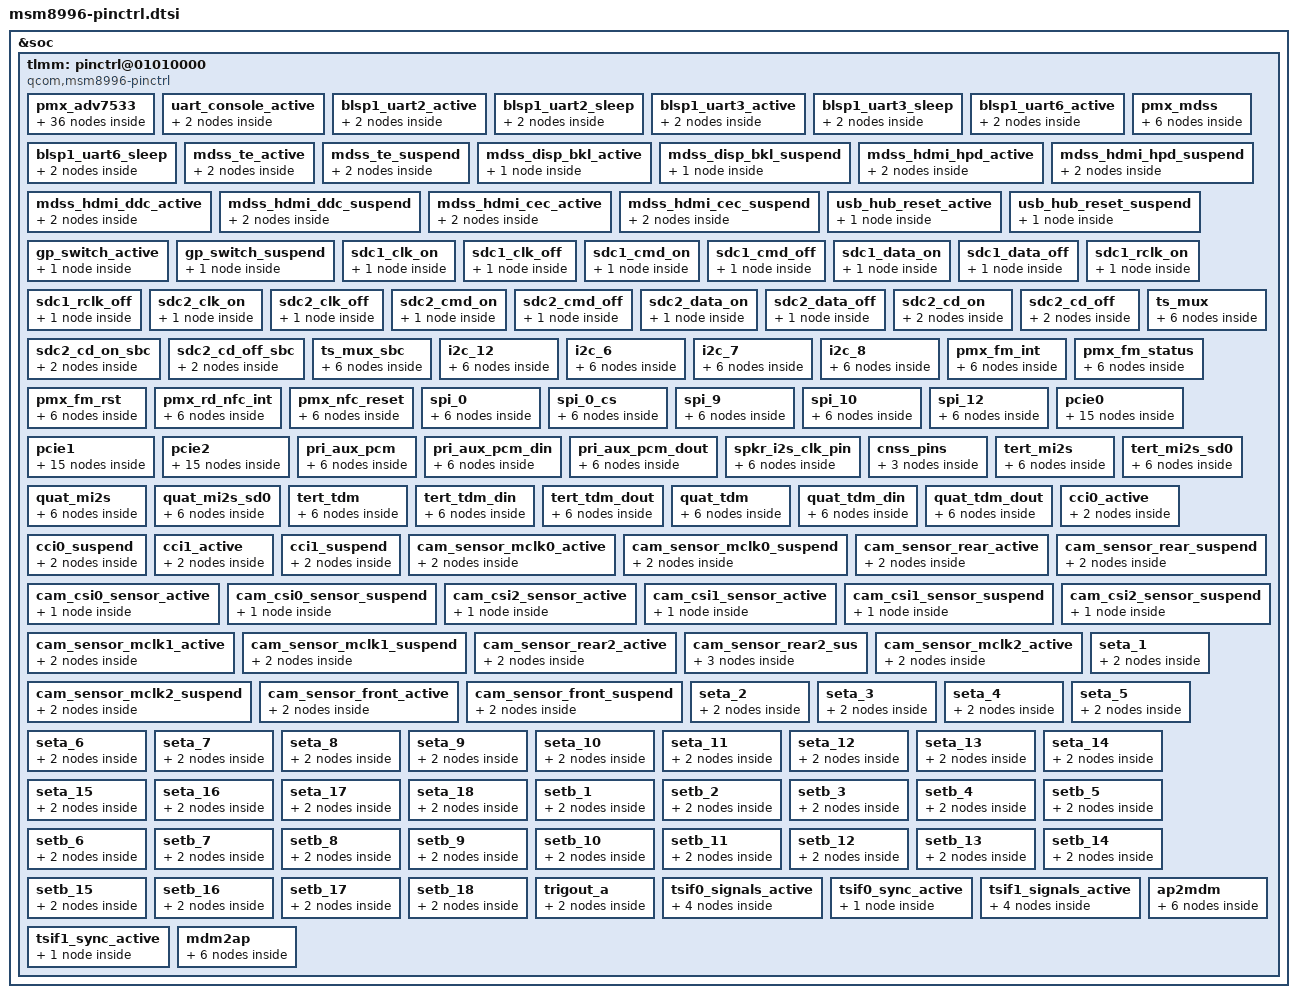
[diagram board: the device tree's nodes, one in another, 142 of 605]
/* Copyright (c) 2014-2015, The Linux Foundation. All rights reserved.
 *
 * This program is free software; you can redistribute it and/or modify
 * it under the terms of the GNU General Public License version 2 and
 * only version 2 as published by the Free Software Foundation.
 *
 * This program is distributed in the hope that it will be useful,
 * but WITHOUT ANY WARRANTY; without even the implied warranty of
 * MERCHANTABILITY or FITNESS FOR A PARTICULAR PURPOSE.  See the
 * GNU General Public License for more details.
 */

&soc {
	tlmm: pinctrl@01010000 {
		compatible = "qcom,msm8996-pinctrl";
		reg = <0x01010000 0x300000>;
		interrupts = <0 208 0>;
		gpio-controller;
		#gpio-cells = <2>;
		interrupt-controller;
		#interrupt-cells = <2>;

		/* add pingrp for adv7533 */
		pmx_adv7533: pmx_adv7533 {
			adv7533_0_int_active: adv7533_0_int_active {
				mux {
					pins = "gpio106";
					function = "gpio";
				};

				config {
					pins = "gpio106";
					drive-strength = <16>; /* 16 mA */
					bias-pull-down; /* pull down */
				};
			};

			adv7533_0_int_suspend: adv7533_0_int_suspend {
				mux {
					pins = "gpio106";
					function = "gpio";
				};

				config {
					pins = "gpio106";
					drive-strength = <16>; /* 16 mA */
					bias-pull-down; /* pull down */
				};
			};

			adv7533_0_hpd_int_active: adv7533_0_hpd_int_active {
				mux {
					pins = "gpio104";
					function = "gpio";
				};

				config {
					pins = "gpio104";
					drive-strength = <16>; /* 16 mA */
					bias-pull-down; /* pull down */
				};
			};

			adv7533_0_hpd_int_suspend: adv7533_0_hpd_int_suspend {
				mux {
					pins = "gpio104";
					function = "gpio";
				};

				config {
					pins = "gpio104";
					drive-strength = <16>; /* 16 mA */
					bias-pull-down; /* pull down */
				};
			};

			adv7533_0_switch_active: adv7533_0_switch_active {
				mux {
					pins = "gpio105";
					function = "gpio";
					bias-pull-down; /* pull down */
				};

				config {
					pins = "gpio105";
					drive-strength = <16>; /* 16 mA */
					bias-pull-down; /* pull down */
				};
			};

			adv7533_0_switch_suspend: adv7533_0_switch_suspend {
				mux {
					pins = "gpio105";
					function = "gpio";
				};

				config {
					pins = "gpio105";
					drive-strength = <16>; /* 16 mA */
				};
			};
			adv7533_1_int_active: adv7533_1_int_active {
				mux {
					pins = "gpio108";
					function = "gpio";
				};

				config {
					pins = "gpio108";
					drive-strength = <16>; /* 16 mA */
					bias-pull-down; /* pull down */
				};
			};

			adv7533_1_int_suspend: adv7533_1_int_suspend {
				mux {
					pins = "gpio108";
					function = "gpio";
				};

				config {
					pins = "gpio108";
					drive-strength = <16>; /* 16 mA */
					bias-pull-down; /* pull down */
				};
			};

			adv7533_1_hpd_int_active: adv7533_1_hpd_int_active {
				mux {
					pins = "gpio103";
					function = "gpio";
				};

				config {
					pins = "gpio103";
					drive-strength = <16>; /* 16 mA */
					bias-pull-down; /* pull down */
				};
			};

			adv7533_1_hpd_int_suspend: adv7533_1_hpd_int_suspend {
				mux {
					pins = "gpio103";
					function = "gpio";
				};

				config {
					pins = "gpio103";
					drive-strength = <16>; /* 16 mA */
					bias-pull-down; /* pull down */
				};
			};

			adv7533_1_switch_active: adv7533_1_switch_active {
				mux {
					pins = "gpio107";
					function = "gpio";
					bias-pull-down; /* pull down */
				};

				config {
					pins = "gpio107";
					drive-strength = <16>; /* 16 mA */
					bias-pull-down; /* pull down */
				};
			};

			adv7533_1_switch_suspend: adv7533_1_switch_suspend {
				mux {
					pins = "gpio107";
					function = "gpio";
				};

				config {
					pins = "gpio107";
					drive-strength = <16>; /* 16 mA */
				};
			};
		};

		uart_console_active: uart_console_active {
			mux {
				pins = "gpio4", "gpio5";
				function = "blsp_uart8";
			};

			config {
				pins = "gpio4", "gpio5";
				drive-strength = <2>;
				bias-disable;
			};
		};

		blsp1_uart2_active: blsp1_uart2_active {
			mux {
				pins = "gpio41", "gpio42", "gpio43", "gpio44";
				function = "blsp_uart2";
			};

			config {
				pins = "gpio41", "gpio42", "gpio43", "gpio44";
				drive-strength = <2>;
				bias-disable;
			};
		};

		blsp1_uart2_sleep: blsp1_uart2_sleep {
			mux {
				pins = "gpio41", "gpio42", "gpio43", "gpio44";
				function = "gpio";
			};

			config {
				pins = "gpio41", "gpio42", "gpio43", "gpio44";
				drive-strength = <2>;
				bias-disable;
			};
		};


		blsp1_uart3_active: blsp1_uart3_active {
			mux {
				pins = "gpio45", "gpio46", "gpio47", "gpio48";
				function = "blsp_uart3";
			};

			config {
				pins = "gpio45", "gpio46", "gpio47", "gpio48";
				drive-strength = <2>;
				bias-disable;
			};
		};

		blsp1_uart3_sleep: blsp1_uart3_sleep {
			mux {
				pins = "gpio45", "gpio46", "gpio47", "gpio48";
				function = "gpio";
			};

			config {
				pins = "gpio45", "gpio46", "gpio47", "gpio48";
				drive-strength = <2>;
				bias-disable;
			};
		};


		blsp1_uart6_active: blsp1_uart6_active {
			mux {
				pins = "gpio25", "gpio26", "gpio27", "gpio28";
				function = "blsp_uart6";
			};

			config {
				pins = "gpio25", "gpio26", "gpio27", "gpio28";
				drive-strength = <2>;
				bias-disable;
			};
		};

		blsp1_uart6_sleep: blsp1_uart6_sleep {
			mux {
				pins = "gpio25", "gpio26", "gpio27", "gpio28";
				function = "gpio";
			};

			config {
				pins = "gpio25", "gpio26", "gpio27", "gpio28";
				drive-strength = <2>;
				bias-disable;
			};
		};


		pmx_mdss: pmx_mdss {
			mdss_dsi_active: mdss_dsi_active {
				mux {
					pins = "gpio8";
					function = "gpio";
				};

				pmx_mdss {
					pins = "gpio8";
					drive-strength = <8>; /* 8 mA */
					bias-disable = <0>; /* no pull */
					output-high;
				};
			};
			mdss_dsi_suspend: mdss_dsi_suspend {
				mux {
					pins = "gpio8";
					function = "gpio";
				};

				config {
					pins = "gpio8";
					drive-strength = <2>; /* 2 mA */
					bias-pull-down; /* pull down */
				};
			};
		};

		mdss_te_active: mdss_te_active {
			mux {
				pins = "gpio10";
				function = "mdp_vsync";
			};
			config {
				pins = "gpio10";
				drive-strength = <2>; /* 8 mA */
				bias-pull-down; /* pull down*/
			};
		};


		mdss_te_suspend: mdss_te_suspend {
			mux {
				pins = "gpio10";
				function = "mdp_vsync";
			};
			config {
				pins = "gpio10";
				drive-strength = <2>; /* 2 mA */
				bias-pull-down; /* pull down */
			};
		};

		mdss_disp_bkl_active: mdss_disp_bkl_active {
			config {
				pins = "gpio135";
				drive-strength = <8>; /* 8 mA */
				bias-disable; /* no pull */
				output-high;
			};
		};

		mdss_disp_bkl_suspend: mdss_disp_bkl_suspend {
			config {
				pins = "gpio135";
				drive-strength = <2>; /* 2 mA */
				bias-pull-down; /* pull down */
			};
		};

		mdss_hdmi_hpd_active: mdss_hdmi_hpd_active {
			mux {
				pins = "gpio34";
				function = "hdmi_hot";
			};

			config {
				pins = "gpio34";
				bias-pull-down;
				drive-strength = <16>;
			};
		};

		mdss_hdmi_hpd_suspend: mdss_hdmi_hpd_suspend {
			mux {
				pins = "gpio34";
				function = "hdmi_hot";
			};

			config {
				pins = "gpio34";
				bias-pull-down;
				drive-strength = <2>;
			};
		};

		mdss_hdmi_ddc_active: mdss_hdmi_ddc_active {
			mux {
				pins = "gpio32", "gpio33";
				function = "hdmi_ddc";
			};

			config {
				pins = "gpio32", "gpio33";
				drive-strength = <2>;
				bias-pull-up;
			};
		};

		mdss_hdmi_ddc_suspend: mdss_hdmi_ddc_suspend {
			mux {
				pins = "gpio32", "gpio33";
				function = "hdmi_ddc";
			};

			config {
				pins = "gpio32", "gpio33";
				drive-strength = <2>;
				bias-pull-down;
			};
		};

		mdss_hdmi_cec_active: mdss_hdmi_cec_active {
			mux {
				pins = "gpio31";
				function = "hdmi_cec";
			};

			config {
				pins = "gpio31";
				drive-strength = <2>;
				bias-pull-up;
			};
		};

		mdss_hdmi_cec_suspend: mdss_hdmi_cec_suspend {
			mux {
				pins = "gpio31";
				function = "hdmi_cec";
			};

			config {
				pins = "gpio31";
				drive-strength = <2>;
				bias-pull-down;
			};
		};

		usb_hub_reset_active: usb_hub_reset_active {
			usb_hub_reset_active {
				pins = "gpio103";
				drive-strength = <8>; /* 8 mA */
				bias-pull-up;  /* pull up */
				output-high;
			};
		};

		usb_hub_reset_suspend: usb_hub_reset_suspend {
			usb_hub_reset_suspend {
				pins = "gpio103";
				drive-strength = <2>; /* 2 mA */
				bias-disable= <0>; /* no pull */
			};
		};


		gp_switch_active: gp_switch_active {
			gp_switch_active {
				pins = "gpio127";
				drive-strength = <8>; /* 8 mA */
				bias-pull-up;  /* pull up */
				output-low;
			};
		};

		gp_switch_suspend: gp_switch_suspend {
			gp_switch_suspend {
				pins = "gpio127";
				drive-strength = <2>; /* 2 mA */
				bias-disable= <0>; /* no pull */
			};
		};


		sdc1_clk_on: sdc1_clk_on {
			config {
				pins = "sdc1_clk";
				bias-disable;		/* NO pull */
				drive-strength = <16>;	/* 16 MA */
			};
		};

		sdc1_clk_off: sdc1_clk_off {
			config {
				pins = "sdc1_clk";
				bias-disable;		/* NO pull */
				drive-strength = <2>;	/* 2 MA */
			};
		};

		sdc1_cmd_on: sdc1_cmd_on {
			config {
				pins = "sdc1_cmd";
				bias-pull-up;		/* pull up */
				drive-strength = <10>;	/* 10 MA */
			};
		};

		sdc1_cmd_off: sdc1_cmd_off {
			config {
				pins = "sdc1_cmd";
				num-grp-pins = <1>;
				bias-pull-up;		/* pull up */
				drive-strength = <2>;	/* 2 MA */
			};
		};

		sdc1_data_on: sdc1_data_on {
			config {
				pins = "sdc1_data";
				bias-pull-up;		/* pull up */
				drive-strength = <10>;	/* 10 MA */
			};
		};

		sdc1_data_off: sdc1_data_off {
			config {
				pins = "sdc1_data";
				bias-pull-up;		/* pull up */
				drive-strength = <2>;	/* 2 MA */
			};
		};

		sdc1_rclk_on: sdc1_rclk_on {
			config {
				pins = "sdc1_rclk";
				bias-pull-down;		/* pull down */
			};
		};

		sdc1_rclk_off: sdc1_rclk_off {
			config {
				pins = "sdc1_rclk";
				bias-pull-down;		/* pull down */
			};
		};

		sdc2_clk_on: sdc2_clk_on {
			config {
				pins = "sdc2_clk";
				bias-disable;		/* NO pull */
				drive-strength = <16>;	/* 16 MA */
			};
		};

		sdc2_clk_off: sdc2_clk_off {
			config {
				pins = "sdc2_clk";
				bias-disable;		/* NO pull */
				drive-strength = <2>;	/* 2 MA */
			};
		};

		sdc2_cmd_on: sdc2_cmd_on {
			config {
				pins = "sdc2_cmd";
				bias-pull-up;		/* pull up */
				drive-strength = <10>;	/* 10 MA */
			};
		};

		sdc2_cmd_off: sdc2_cmd_off {
			config {
				pins = "sdc2_cmd";
				bias-pull-up;		/* pull up */
				drive-strength = <2>;	/* 2 MA */
			};
		};

		sdc2_data_on: sdc2_data_on {
			config {
				pins = "sdc2_data";
				bias-pull-up;		/* pull up */
				drive-strength = <10>;	/* 10 MA */
			};
		};

		sdc2_data_off: sdc2_data_off {
			config {
				pins = "sdc2_data";
				bias-pull-up;		/* pull up */
				drive-strength = <2>;	/* 2 MA */
			};
		};

		sdc2_cd_on: sdc2_cd_on {
			mux {
				pins = "gpio95";
				function = "gpio";
			};

			config {
				pins = "gpio95";
				bias-pull-up;		/* pull up */
				drive-strength = <16>;	/* 16 MA */
			};
		};

		sdc2_cd_off: sdc2_cd_off {
			mux {
				pins = "gpio95";
				function = "gpio";
			};

			config {
				pins = "gpio95";
				bias-pull-up;		/* pull up */
				drive-strength = <2>;	/* 2 MA */
			};
		};

		sdc2_cd_on_sbc: sdc2_cd_on_sbc {
			mux {
				pins = "gpio38";
				function = "gpio";
			};

			config {
				pins = "gpio38";
				bias-pull-up;		/* pull up */
				drive-strength = <16>;	/* 16 MA */
			};
		};

		sdc2_cd_off_sbc: sdc2_cd_off_sbc {
			mux {
				pins = "gpio38";
				function = "gpio";
			};

			config {
				pins = "gpio38";
				bias-pull-up;		/* pull up */
				drive-strength = <2>;	/* 2 MA */
			};
		};

		ts_mux {
			ts_active: ts_active {
				mux {
					pins = "gpio89", "gpio125";
					function = "gpio";
				};

				config {
					pins = "gpio89", "gpio125";
					drive-strength = <16>;
					bias-pull-up;
				};
			};

			ts_suspend: ts_suspend {
				mux {
					pins = "gpio89", "gpio125";
					function = "gpio";
				};

				config {
					pins = "gpio89", "gpio125";
					drive-strength = <2>;
					bias-disable;
				};
			};
		};

		ts_mux_sbc {
			ts_active_sbc: ts_active_sbc {
				mux {
					pins = "gpio29", "gpio125";
					function = "gpio";
				};

				config_sbc {
					pins = "gpio29", "gpio125";
					drive-strength = <16>;
					bias-pull-up;
				};
		};

			ts_suspend_sbc: ts_suspend_sbc {
				mux {
					pins = "gpio29", "gpio125";
					function = "gpio";
				};

				config {
					pins = "gpio29", "gpio125";
					drive-strength = <2>;
					bias-disable;
				};
			};
		};
		i2c_12 {
                        i2c_12_active: i2c_12_active {
				mux {
					pins = "gpio87", "gpio88";
					function = "blsp_i2c12";
				};

				config {
					pins = "gpio87", "gpio88";
					drive-strength = <2>;
					bias-disable;
				};
			};

			i2c_12_sleep: i2c_12_sleep {
				mux {
					pins = "gpio87", "gpio88";
					function = "blsp_i2c12";
				};

				config {
					pins = "gpio87", "gpio88";
					drive-strength = <2>;
					bias-pull-up;
				};
			};
		};

		i2c_6 {
			i2c_6_active: i2c_6_active {
				mux {
					pins = "gpio27", "gpio28";
					function = "blsp_i2c6";
				};

				config {
					pins = "gpio27", "gpio28";
					drive-strength = <2>;
					bias-disable;
				};
			};

			i2c_6_sleep: i2c_6_sleep {
				mux {
					pins = "gpio27", "gpio28";
					function = "blsp_i2c6";
				};

				config {
					pins = "gpio27", "gpio28";
					drive-strength = <2>;
					bias-pull-up;
				};
			};
		};

		i2c_7 {
			i2c_7_active: i2c_7_active {
				mux {
					pins = "gpio55", "gpio56";
					function = "blsp_i2c7";
				};

				config {
					pins = "gpio55", "gpio56";
					drive-strength = <2>;
					bias-disable;
				};
			};

			i2c_7_sleep: i2c_7_sleep {
				mux {
					pins = "gpio55", "gpio56";
					function = "blsp_i2c7";
				};

				config {
					pins = "gpio55", "gpio56";
					drive-strength = <2>;
					bias-pull-up;
				};
			};
		};

		i2c_8 {
			i2c_8_active: i2c_8_active {
				mux {
					pins = "gpio6", "gpio7";
					function = "blsp_i2c8";
				};

				config {
					pins = "gpio6", "gpio7";
					drive-strength = <4>;
					bias-disable;
				};
			};

			i2c_8_sleep: i2c_8_sleep {
				mux {
					pins = "gpio6", "gpio7";
					function = "blsp_i2c8";
				};

				config {
					pins = "gpio6", "gpio7";
					drive-strength = <4>;
					bias-pull-up;
				};
			};
		};

		pmx_fm_int {
			fm_int_active: fm_int_active {
				mux {
					pins = "gpio38";
					function = "gpio";
				};

				config {
					pins = "gpio38";
					drive-strength = <16>;
					bias-pull-up;
				};
			};

		fm_int_suspend: fm_int_suspend {
				mux {
					pins = "gpio38";
					function = "gpio";
				};

				config {
					pins = "gpio38";
					drive-strength = <16>;
					bias-pull-up;
				};
			};
		};

		pmx_fm_status {
			fm_status_int_active: fm_status_int_active {
				mux {
					pins = "gpio78";
					function = "gpio";
				};

				config {
					pins = "gpio78";
					drive-strength = <16>;
					bias-pull-up;
				};
			};

			fm_status_int_suspend: fm_status_int_suspend {
				mux {
					pins = "gpio78";
					function = "gpio";
				};

				config {
					pins = "gpio78";
					drive-strength = <16>;
					bias-pull-up;
				};
			};
		};

		pmx_fm_rst {
			fm_rst_active: fm_rst_active {
				mux {
					pins = "gpio39";
					function = "gpio";
				};

				config {
					pins = "gpio39";
					drive-strength = <16>;
					bias-pull-down;
				};
			};

			fm_rst_suspend: fm_rst_suspend {
				mux {
					pins = "gpio39";
					function = "gpio";
				};

				config {
					pins = "gpio39";
					drive-strength = <16>;
					bias-pull-down;
				};
			};
		};

		pmx_rd_nfc_int {
			nfc_int_active: active {
				mux {
					pins = "gpio9";
					function = "gpio";
				};

				config {
					pins = "gpio9";
					drive-strength = <6>;
					bias-pull-up;
				};
			};

			nfc_int_suspend: suspend {
				mux {
					pins = "gpio9";
					function = "gpio";
				};

				config {
					pins = "gpio9";
					drive-strength = <6>;
					bias-pull-up;
				};
			};
		};

		pmx_nfc_reset {
			nfc_disable_active: active {
				mux {
					pins = "gpio12";
					function = "gpio";
				};

				config {
					pins = "gpio12";
					drive-strength = <6>;
					bias-pull-up;
				};
			};

			nfc_disable_suspend: suspend {
				mux {
					pins = "gpio12";
					function = "gpio";
				};

				config {
					pins = "gpio12";
					drive-strength = <6>;
					bias-disable;
				};
			};
		};

		spi_0 {
			spi_0_active: spi_0_active {
				mux {
					pins = "gpio0", "gpio1",
						"gpio2", "gpio3";
					function = "blsp_spi1";
				};

				config {
					pins = "gpio0", "gpio1",
						"gpio2", "gpio3";
					drive-strength = <6>;
					bias-disable;
				};
			};

			spi_0_sleep: spi_0_sleep {
				mux {
					pins = "gpio0", "gpio1",
						"gpio2", "gpio3";
					function = "blsp_spi1";
				};

				config {
					pins = "gpio0", "gpio1",
						"gpio2", "gpio3";
					drive-strength = <6>;
					bias-disable;
				};
			};
		};

		spi_0_cs {
			spi_0_cs_active: spi_0_cs_active {
				mux {
					pins = "gpio24", "gpio90";
					function = "blsp1_spi";
				};

				config {
					pins = "gpio24", "gpio90";
					drive-strength = <6>;
					bias-pull-up;
				};
			};

			spi_0_cs_sleep: spi_0_cs_sleep {
				mux {
					pins = "gpio24", "gpio90";
					function = "blsp1_spi";
				};

				config {
					pins = "gpio24", "gpio90";
					drive-strength = <6>;
					bias-pull-up;
				};
			};
		};

		spi_9 {
			spi_9_active: spi_9_active {
				mux {
					pins = "gpio49", "gpio50", "gpio51",
								"gpio52";
					function = "blsp_spi9";
				};

				config {
					pins = "gpio49", "gpio50", "gpio51",
								"gpio52";
					drive-strength = <6>;
					bias-disable;
				};
			};

			spi_9_sleep: spi_9_sleep {
				mux {
					pins = "gpio49", "gpio50", "gpio51",
								"gpio52";
					function = "blsp_spi9";
				};

				config {
					pins = "gpio49", "gpio50", "gpio51",
								"gpio52";
					drive-strength = <6>;
					bias-disable;
				};
			};
		};

		spi_10 {
			spi_10_active: spi_10_active {
				mux {
					pins = "gpio8", "gpio9", "gpio10",
								"gpio11";
					function = "blsp_spi10";
				};

				config {
					pins = "gpio8", "gpio9", "gpio10",
								"gpio11";
					drive-strength = <6>;
					bias-disable;
				};
			};

			spi_10_sleep: spi_10_sleep {
				mux {
					pins = "gpio8", "gpio9", "gpio10",
								"gpio11";
					function = "blsp_spi10";
				};

				config {
					pins = "gpio8", "gpio9", "gpio10",
								"gpio11";
					drive-strength = <6>;
					bias-disable;
				};
			};
		};

		spi_12 {
			spi_12_active: spi_12_active {
				mux {
					pins = "gpio85", "gpio86", "gpio87",
								"gpio88";
					function = "blsp_spi12";
				};

				config {
					pins = "gpio85", "gpio86", "gpio87",
								"gpio88";
					drive-strength = <6>;
					bias-disable;
				};
			};

			spi_12_sleep: spi_12_sleep {
				mux {
					pins = "gpio85", "gpio86", "gpio87",
								"gpio88";
					function = "blsp_spi12";
				};

				config {
					pins = "gpio85", "gpio86", "gpio87",
								"gpio88";
					drive-strength = <6>;
					bias-disable;
				};
			};
		};

		pcie0 {
			pcie0_clkreq_default: pcie0_clkreq_default {
				mux {
					pins = "gpio36";
					function = "pci_e0";
				};

				config {
					pins = "gpio36";
					drive-strength = <2>;
					bias-pull-up;
				};
			};

			pcie0_perst_default: pcie0_perst_default {
				mux {
					pins = "gpio35";
					function = "gpio";
				};

				config {
					pins = "gpio35";
					drive-strength = <2>;
					bias-pull-down;
				};
			};

			pcie0_wake_default: pcie0_wake_default {
				mux {
					pins = "gpio37";
					function = "gpio";
				};

				config {
					pins = "gpio37";
					drive-strength = <2>;
					bias-pull-up;
				};
			};

			pcie0_clkreq_sleep: pcie0_clkreq_sleep {
				mux {
					pins = "gpio36";
					function = "gpio";
				};

				config {
					pins = "gpio36";
					drive-strength = <2>;
					bias-disable;
				};
			};

			pcie0_wake_sleep: pcie0_wake_sleep {
				mux {
					pins = "gpio37";
					function = "gpio";
				};

				config {
					pins = "gpio37";
					drive-strength = <2>;
					bias-disable;
				};
			};
		};

		pcie1 {
			pcie1_clkreq_default: pcie1_clkreq_default {
				mux {
					pins = "gpio131";
					function = "pci_e1";
				};

				config {
					pins = "gpio131";
					drive-strength = <2>;
					bias-pull-up;
				};
			};

			pcie1_perst_default: pcie1_perst_default {
				mux {
					pins = "gpio130";
					function = "gpio";
				};

				config {
					pins = "gpio130";
					drive-strength = <2>;
					bias-pull-down;
				};
			};

			pcie1_wake_default: pcie1_wake_default {
				mux {
					pins = "gpio132";
					function = "gpio";
				};

				config {
					pins = "gpio132";
					drive-strength = <2>;
					bias-pull-down;
				};
			};

			pcie1_clkreq_sleep: pcie1_clkreq_sleep {
				mux {
					pins = "gpio131";
					function = "gpio";
				};

				config {
					pins = "gpio131";
					drive-strength = <2>;
					bias-disable;
				};
			};

			pcie1_wake_sleep: pcie1_wake_sleep {
				mux {
					pins = "gpio132";
					function = "gpio";
				};

				config {
					pins = "gpio132";
					drive-strength = <2>;
					bias-disable;
				};
			};
		};

		pcie2 {
			pcie2_clkreq_default: pcie2_clkreq_default {
				mux {
					pins = "gpio115";
					function = "pci_e2";
				};

				config {
					pins = "gpio115";
					drive-strength = <2>;
					bias-pull-up;
				};
			};

			pcie2_perst_default: pcie2_perst_default {
				mux {
					pins = "gpio114";
					function = "gpio";
				};

				config {
					pins = "gpio114";
					drive-strength = <2>;
					bias-pull-down;
				};
			};

			pcie2_wake_default: pcie2_wake_default {
				mux {
					pins = "gpio116";
					function = "gpio";
				};

				config {
					pins = "gpio116";
					drive-strength = <2>;
					bias-pull-down;
				};
			};

			pcie2_clkreq_sleep: pcie2_clkreq_sleep {
				mux {
					pins = "gpio115";
					function = "gpio";
				};

				config {
					pins = "gpio115";
					drive-strength = <2>;
					bias-disable;
				};
			};

			pcie2_wake_sleep: pcie2_wake_sleep {
				mux {
					pins = "gpio116";
					function = "gpio";
				};

				config {
					pins = "gpio116";
					drive-strength = <2>;
					bias-disable;
				};
			};
		};

		pri_aux_pcm {
			pri_aux_pcm_sleep: pri_aux_pcm_sleep {
				mux {
					pins = "gpio65", "gpio66";
					function = "pri_mi2s";
				};

				config {
					pins = "gpio65", "gpio66";
					drive-strength = <2>;   /* 2 mA */
					bias-pull-down;         /* PULL DOWN */
				};
			};
			pri_aux_pcm_active: pri_aux_pcm_active {
				mux {
					pins = "gpio65", "gpio66";
					function = "pri_mi2s";
				};

				config {
					pins = "gpio65", "gpio66";
					drive-strength = <8>;   /* 8 mA */
					bias-disable;           /* NO PULL */
					output-high;
				};
			};
		};

		pri_aux_pcm_din {
			pri_aux_pcm_din_sleep: pri_aux_pcm_din_sleep {
				mux {
					pins = "gpio67";
					function = "pri_mi2s";
				};

				config {
					pins = "gpio67";
					drive-strength = <2>;   /* 2 mA */
					bias-pull-down;         /* PULL DOWN */
				};
			};
			pri_aux_pcm_din_active: pri_aux_pcm_din_active {
				mux {
					pins = "gpio67";
					function = "pri_mi2s";
				};

				config {
					pins = "gpio67";
					drive-strength = <8>;   /* 8 mA */
					bias-disable;           /* NO PULL */
				};
			};
		};

		pri_aux_pcm_dout {
			pri_aux_pcm_dout_sleep: pri_aux_pcm_dout_sleep {
				mux {
					pins = "gpio68";
					function = "pri_mi2s";
				};

				config {
					pins = "gpio68";
					drive-strength = <2>;   /* 2 mA */
					bias-pull-down;         /* PULL DOWN */
				};
			};
			pri_aux_pcm_dout_active: pri_aux_pcm_dout_active {
				mux {
					pins = "gpio68";
					function = "pri_mi2s";
				};

				config {
					pins = "gpio68";
					drive-strength = <8>;   /* 8 mA */
					bias-disable;           /* NO PULL */
				};
			};
		};

		spkr_i2s_clk_pin {
			spkr_i2s_clk_sleep: spkr_i2s_clk_sleep {
				mux {
					pins = "gpio69";
					function = "spkr_i2s";
				};

				config {
					pins = "gpio69";
					drive-strength = <2>; /* 2 mA */
					bias-pull-down;       /* PULL DOWN */
				};
			};
			spkr_i2s_clk_active: spkr_i2s_clk_active {
				mux {
					pins = "gpio69";
					function = "spkr_i2s";
				};

				config {
					pins = "gpio69";
					drive-strength = <8>; /* 8 mA */
					bias-disable;         /* NO PULL */
				};
			};
		};

		cnss_pins {
			cnss_default: cnss_default {
				mux {
					pins = "gpio46";
					function = "gpio";
				};

				config {
					pins = "gpio46";
					drive-strength = <16>;
					bias-pull-down;
				};
			};
		};

		tert_mi2s {
			tert_mi2s_sleep: tert_mi2s_sleep {
				mux {
					pins = "gpio75", "gpio76";
					function = "ter_mi2s";
				};

				config {
					pins = "gpio75", "gpio76";
					drive-strength = <2>;   /* 2 mA */
					bias-pull-down;         /* PULL DOWN */
				};
			};
			tert_mi2s_active: tert_mi2s_active {
				mux {
					pins = "gpio75", "gpio76";
					function = "ter_mi2s";
				};

				config {
					pins = "gpio75", "gpio76";
					drive-strength = <8>;   /* 8 mA */
					bias-disable;           /* NO PULL */
					output-high;
				};
			};
		};

		tert_mi2s_sd0 {
			tert_mi2s_sd0_sleep: tert_mi2s_sd0_sleep {
				mux {
					pins = "gpio77";
					function = "ter_mi2s";
				};

				config {
					pins = "gpio77";
					drive-strength = <2>;   /* 2 mA */
					bias-pull-down;         /* PULL DOWN */
				};
			};
			tert_mi2s_sd0_active: tert_mi2s_sd0_active {
				mux {
					pins = "gpio77";
					function = "ter_mi2s";
				};

				config {
					pins = "gpio77";
					drive-strength = <8>;   /* 8 mA */
					bias-disable;           /* NO PULL */
				};
			};
		};

		quat_mi2s {
			quat_mi2s_sleep: quat_mi2s_sleep {
				mux {
					pins = "gpio58", "gpio59";
					function = "qua_mi2s";
				};

				config {
					pins = "gpio58", "gpio59";
					drive-strength = <2>;   /* 2 mA */
					bias-pull-down;         /* PULL DOWN */
				};
			};
			quat_mi2s_active: quat_mi2s_active {
				mux {
					pins = "gpio58", "gpio59";
					function = "qua_mi2s";
				};

				config {
					pins = "gpio58", "gpio59";
					drive-strength = <8>;   /* 8 mA */
					bias-disable;           /* NO PULL */
					output-high;
				};
			};
		};

		quat_mi2s_sd0 {
			quat_mi2s_sd0_sleep: quat_mi2s_sd0_sleep {
				mux {
					pins = "gpio60";
					function = "qua_mi2s";
				};

				config {
					pins = "gpio60";
					drive-strength = <2>;   /* 2 mA */
					bias-pull-down;         /* PULL DOWN */
				};
			};
			quat_mi2s_sd0_active: quat_mi2s_sd0_active {
				mux {
					pins = "gpio60";
					function = "qua_mi2s";
				};

				config {
					pins = "gpio60";
					drive-strength = <8>;   /* 8 mA */
					bias-disable;           /* NO PULL */
				};
			};
		};

		tert_tdm {
			tert_tdm_sleep: tert_tdm_sleep {
				mux {
					pins = "gpio75", "gpio76";
					function = "ter_mi2s";
				};

				config {
					pins = "gpio75", "gpio76";
					drive-strength = <2>;   /* 2 mA */
					bias-pull-down;         /* PULL DOWN */
				};
			};
			tert_tdm_active: tert_tdm_active {
				mux {
					pins = "gpio75", "gpio76";
					function = "ter_mi2s";
				};

				config {
					pins = "gpio75", "gpio76";
					drive-strength = <8>;   /* 8 mA */
					bias-disable;           /* NO PULL */
					output-high;
				};
			};
		};

		tert_tdm_din {
			tert_tdm_din_sleep: tert_tdm_din_sleep {
				mux {
					pins = "gpio77";
					function = "ter_mi2s";
				};

				config {
					pins = "gpio77";
					drive-strength = <2>;   /* 2 mA */
					bias-pull-down;         /* PULL DOWN */
				};
			};
			tert_tdm_din_active: tert_tdm_din_active {
				mux {
					pins = "gpio77";
					function = "ter_mi2s";
				};

				config {
					pins = "gpio77";
					drive-strength = <8>;   /* 8 mA */
					bias-disable;           /* NO PULL */
				};
			};
		};

		tert_tdm_dout {
			tert_tdm_dout_sleep: tert_tdm_dout_sleep {
				mux {
					pins = "gpio78";
					function = "ter_mi2s";
				};

				config {
					pins = "gpio78";
					drive-strength = <2>;   /* 2 mA */
					bias-pull-down;         /* PULL DOWN */
				};
			};
			tert_tdm_dout_active: tert_tdm_dout_active {
				mux {
					pins = "gpio78";
					function = "ter_mi2s";
				};

				config {
					pins = "gpio78";
					drive-strength = <8>;   /* 8 mA */
					bias-disable;           /* NO PULL */
				};
			};
		};

		quat_tdm {
			quat_tdm_sleep: quat_tdm_sleep {
				mux {
					pins = "gpio58", "gpio59";
					function = "qua_mi2s";
				};

				config {
					pins = "gpio58", "gpio59";
					drive-strength = <2>;   /* 2 mA */
					bias-pull-down;         /* PULL DOWN */
				};
			};
			quat_tdm_active: quat_tdm_active {
				mux {
					pins = "gpio58", "gpio59";
					function = "qua_mi2s";
				};

				config {
					pins = "gpio58", "gpio59";
					drive-strength = <8>;   /* 8 mA */
					bias-disable;           /* NO PULL */
					output-high;
				};
			};
		};

		quat_tdm_din {
			quat_tdm_din_sleep: quat_tdm_din_sleep {
				mux {
					pins = "gpio60";
					function = "qua_mi2s";
				};

				config {
					pins = "gpio60";
					drive-strength = <2>;   /* 2 mA */
					bias-pull-down;         /* PULL DOWN */
				};
			};
			quat_tdm_din_active: quat_tdm_din_active {
				mux {
					pins = "gpio60";
					function = "qua_mi2s";
				};

				config {
					pins = "gpio60";
					drive-strength = <8>;   /* 8 mA */
					bias-disable;           /* NO PULL */
				};
			};
		};

		quat_tdm_dout {
			quat_tdm_dout_sleep: quat_tdm_dout_sleep {
				mux {
					pins = "gpio61";
					function = "qua_mi2s";
				};

				config {
					pins = "gpio61";
					drive-strength = <2>;   /* 2 mA */
					bias-pull-down;         /* PULL DOWN */
				};
			};
			quat_tdm_dout_active: quat_tdm_dout_active {
				mux {
					pins = "gpio61";
					function = "qua_mi2s";
				};

				config {
					pins = "gpio61";
					drive-strength = <8>;   /* 8 mA */
					bias-disable;           /* NO PULL */
				};
			};
		};

		cci0_active: cci0_active {
			mux {
				/* CLK, DATA */
				pins = "gpio17","gpio18"; // Only 2
				function = "cci_i2c";
			};

			config {
				pins = "gpio17","gpio18";
				bias-pull-up; /* PULL UP*/
				drive-strength = <2>; /* 2 MA */
			};
		};

		cci0_suspend: cci0_suspend {
			mux {
				/* CLK, DATA */
				pins = "gpio17","gpio18";
				function = "cci_i2c";
			};

			config {
				pins = "gpio17","gpio18";
				bias-pull-down; /* PULL DOWN */
				drive-strength = <2>; /* 2 MA */
			};
		};

		cci1_active: cci1_active {
			mux {
				/* CLK, DATA */
				pins = "gpio19","gpio20";
				function = "cci_i2c";
			};

			config {
				pins = "gpio19","gpio20";
				bias-pull-up; /* PULL UP*/
				drive-strength = <2>; /* 2 MA */
			};
		};

		cci1_suspend: cci1_suspend {
			mux {
				/* CLK, DATA */
				pins = "gpio19","gpio20";
				function = "cci_i2c";
			};

			config {
				pins = "gpio19","gpio20";
				bias-pull-down; /* PULL DOWN */
				drive-strength = <2>; /* 2 MA */
			};
		};

		cam_sensor_mclk0_active: cam_sensor_mclk0_active {
			/* MCLK0 */
			mux {
				/* CLK, DATA */
				pins = "gpio13";
				function = "cam_mclk";
			};

			config {
				pins = "gpio13";
				bias-disable; /* No PULL */
				drive-strength = <2>; /* 2 MA */
			};
		};

		cam_sensor_mclk0_suspend: cam_sensor_mclk0_suspend {
			/* MCLK0 */
			mux {
				/* CLK, DATA */
				pins = "gpio13";
				function = "cam_mclk";
			};

			config {
				pins = "gpio13";
				bias-pull-down; /* PULL DOWN */
				drive-strength = <2>; /* 2 MA */
			};
		};

		cam_sensor_rear_active: cam_sensor_rear_active {
			/* RESET, STANDBY */
			mux {
				pins = "gpio30";
				function = "gpio";
			};

			config {
				pins = "gpio30","gpio29";
				bias-disable; /* No PULL */
				drive-strength = <2>; /* 2 MA */
			};
		};

		cam_sensor_rear_suspend: cam_sensor_rear_suspend{
			/* RESET, STANDBY */
			mux {
				pins = "gpio30","gpio29";
				function = "gpio";
			};

			config {
				pins = "gpio30","gpio29";
				bias-disable; /* No PULL */
				drive-strength = <2>; /* 2 MA */
			};
		};

		cam_csi0_sensor_active: cam_csi0_sensor_active {
			/* RESET, STANDBY */
			cam_rear_active_cfg {
				pins = "gpio25","gpio26";
				bias-disable; /* No PULL */
				drive-strength = <2>; /* 2 MA */
			};
		};

		cam_csi0_sensor_suspend: cam_csi0_sensor_suspend{
			/* RESET, STANDBY */
			cam_rear_suspend_cfg {
				pins = "gpio25","gpio26";
				bias-disable; /* No PULL */
				drive-strength = <2>; /* 2 MA */
			};
		};

		cam_csi2_sensor_active: cam_csi2_sensor_active {
			/* RESET, STANDBY */
			cam_rear_active_cfg {
				pins = "gpio23","gpio133";
				bias-disable; /* No PULL */
				drive-strength = <2>; /* 2 MA */
			};
		};

		cam_csi1_sensor_active: cam_csi1_sensor_active {
			/* RESET, STANDBY */
			cam_rear_active_cfg {
				pins = "gpio104","gpio98";
				bias-disable; /* No PULL */
				drive-strength = <2>; /* 2 MA */
			};
		};

		cam_csi1_sensor_suspend: cam_csi1_sensor_suspend {
			/* RESET, STANDBY */
			cam_rear_suspend_cfg {
				pins = "gpio104","gpio98";
				bias-disable; /* No PULL */
				drive-strength = <2>; /* 2 MA */
			};
		};

		cam_csi2_sensor_suspend: cam_csi2_sensor_suspend{
			/* RESET, STANDBY */
			cam_rear_suspend_cfg {
				pins = "gpio23","gpio133";
				bias-disable; /* No PULL */
				drive-strength = <2>; /* 2 MA */
			};
		};

		cam_sensor_mclk1_active: cam_sensor_mclk1_active{
			/* MCLK1 */
			mux {
				/* CLK, DATA */
				pins = "gpio14";
				function = "cam_mclk";
			};

			config {
				pins = "gpio14";
				bias-disable; /* No PULL */
				drive-strength = <2>; /* 2 MA */
			};
		};

		cam_sensor_mclk1_suspend: cam_sensor_mclk1_suspend {
			/* MCLK1 */
			mux {
				/* CLK, DATA */
				pins = "gpio14";
				function = "cam_mclk";
			};

			config {
				pins = "gpio14";
				bias-pull-down; /* PULL DOWN */
				drive-strength = <2>; /* 2 MA */
			};
		};

		cam_sensor_rear2_active: cam_sensor_rear2_active {
			/* RESET, STANDBY */
			mux {
				pins = "gpio63","gpio62";
				function = "gpio";
			};

			config {
				pins = "gpio63","gpio62";
				bias-disable; /* No PULL */
				drive-strength = <2>; /* 2 MA */
			};
		};

		cam_sensor_rear2_sus {
			cam_sensor_rear2_suspend: cam_sensor_rear2_suspend{
				/* RESET, STANDBY */
				mux {
					pins = "gpio63","gpio62";
					function = "gpio";
				};

				config {
					pins = "gpio63","gpio62";
					bias-disable; /* No PULL */
					drive-strength = <2>; /* 2 MA */
				};
			};
		};

		cam_sensor_mclk2_active: cam_sensor_mclk2_active {
			/* MCLK1 */
			mux {
				/* CLK, DATA */
				pins = "gpio15";
				function = "cam_mclk";
			};

			config {
				pins = "gpio15";
				bias-disable; /* No PULL */
				drive-strength = <2>; /* 2 MA */
			};
		};

		cam_sensor_mclk2_suspend: cam_sensor_mclk2_suspend{
			/* MCLK1 */
			mux {
				/* CLK, DATA */
				pins = "gpio15";
				function = "cam_mclk";
			};

			config {
				pins = "gpio15";
				bias-pull-down; /* PULL DOWN */
				drive-strength = <2>; /* 2 MA */
			};
		};

		cam_sensor_front_active: cam_sensor_front_active{
			/* RESET, STANDBY */
			mux {
				pins = "gpio23","gpio26";
				function = "gpio";
			};

			config {
				pins = "gpio23","gpio26";
				bias-disable; /* No PULL */
				drive-strength = <2>; /* 2 MA */
			};
		};

		cam_sensor_front_suspend: cam_sensor_front_suspend{
			/* RESET, STANDBY */
			mux {
				pins = "gpio23","gpio26";
				function = "gpio";
			};

			config {
				pins = "gpio23","gpio26";
				bias-disable; /* No PULL */
				drive-strength = <2>; /* 2 MA */
			};
		};

		/* CoreSight */
		seta_1: seta_1 {
			mux {
				pins = "gpio27";
				function = "gpio";
			};

			config {
				pins = "gpio27";
				function = "qdss_tracectl_a";
				drive-strength = <16>;
				bias-disable;
			};
		};

		seta_2: seta_2 {
			mux {
				pins = "gpio28";
				function = "qdss_tracectl_a";
			};

			config {
				pins = "gpio28";
				drive-strength = <16>;
				bias-disable;
			};
		};

		seta_3: seta_3 {
			mux {
				pins = "gpio53";
				function = "qdss_tracedata_a";
			};

			config {
				pins = "gpio53";
				drive-strength = <16>;
				bias-disable;
			};
		};

		seta_4: seta_4 {
			mux {
				pins = "gpio54";
				function = "qdss_tracedata_a";
			};

			config {
				pins = "gpio54";
				drive-strength = <16>;
				bias-disable;
			};
		};

		seta_5: seta_5 {
			mux {
				pins = "gpio63";
				function = "qdss_tracedata_a";
			};

			config {
				pins = "gpio63";
				drive-strength = <16>;
				bias-disable;
			};
		};

		seta_6: seta_6 {
			mux {
				pins = "gpio64";
				function = "qdss_tracedata_a";
			};

			config {
				pins = "gpio64";
				drive-strength = <16>;
				bias-disable;
			};
		};

		seta_7: seta_7 {
			mux {
				pins = "gpio65";
				function = "qdss_tracedata_a";
			};

			config {
				pins = "gpio65";
				drive-strength = <16>;
				bias-disable;
			};
		};

		seta_8: seta_8 {
			mux {
				pins = "gpio66";
				function = "qdss_tracedata_a";
			};

			config {
				pins = "gpio66";
				drive-strength = <16>;
				bias-disable;
			};
		};

		seta_9: seta_9 {
			mux {
				pins = "gpio67";
				function = "qdss_tracedata_a";
			};

			config {
				pins = "gpio67";
				drive-strength = <16>;
				bias-disable;
			};
		};

		seta_10: seta_10 {
			mux {
				pins = "gpio74";
				function = "qdss_tracedata_a";
			};

			config {
				pins = "gpio74";
				drive-strength = <16>;
				bias-disable;
			};
		};

		seta_11: seta_11 {
			mux {
				pins = "gpio75";
				function = "qdss_tracedata_a";
			};

			config {
				pins = "gpio75";
				drive-strength = <16>;
				bias-disable;
			};
		};

		seta_12: seta_12 {
			mux {
				pins = "gpio76";
				function = "qdss_tracedata_a";
			};

			config {
				pins = "gpio76";
				drive-strength = <16>;
				bias-disable;
			};
		};

		seta_13: seta_13 {
			mux {
				pins = "gpio77";
				function = "qdss_tracedata_a";
			};

			config {
				pins = "gpio77";
				drive-strength = <16>;
				bias-disable;
			};
		};

		seta_14: seta_14 {
			mux {
				pins = "gpio85";
				function = "qdss_tracedata_a";
			};

			config {
				pins = "gpio85";
				drive-strength = <16>;
				bias-disable;
			};
		};

		seta_15: seta_15 {
			mux {
				pins = "gpio86";
				function = "qdss_tracedata_a";
			};

			config {
				pins = "gpio86";
				drive-strength = <16>;
				bias-disable;
			};
		};

		seta_16: seta_16 {
			mux {
				pins = "gpio87";
				function = "qdss_tracedata_a";
			};

			config {
				pins = "gpio87";
				drive-strength = <16>;
				bias-disable;
			};
		};

		seta_17: seta_17 {
			mux {
				pins = "gpio89";
				function = "qdss_tracedata_a";
			};

			config {
				pins = "gpio89";
				drive-strength = <16>;
				bias-disable;
			};
		};

		seta_18: seta_18 {
			mux {
				pins = "gpio90";
				function = "qdss_tracedata_a";
			};

			config {
				pins = "gpio90";
				drive-strength = <16>;
				bias-disable;
			};
		};

		setb_1: setb_1 {
			mux {
				pins = "gpio13";
				function = "qdss_tracedata_b";
			};

			config {
				pins = "gpio13";
				drive-strength = <16>;
				bias-disable;
			};
		};

		setb_2: setb_2 {
			mux {
				pins = "gpio14";
				function = "qdss_tracedata_b";
			};

			config {
				pins = "gpio14";
				drive-strength = <16>;
				bias-disable;
			};
		};

		setb_3: setb_3 {
			mux {
				pins = "gpio15";
				function = "qdss_tracedata_b";
			};

			config {
				pins = "gpio15";
				drive-strength = <16>;
				bias-disable;
			};
		};

		setb_4: setb_4 {
			mux {
				pins = "gpio16";
				function = "qdss_tracedata_b";
			};

			config {
				pins = "gpio16";
				drive-strength = <16>;
				bias-disable;
			};
		};

		setb_5: setb_5 {
			mux {
				pins = "gpio17";
				function = "qdss_tracedata_b";
			};

			config {
				pins = "gpio17";
				drive-strength = <16>;
				bias-disable;
			};
		};

		setb_6: setb_6 {
			mux {
				pins = "gpio18";
				function = "qdss_tracedata_b";
			};

			config {
				pins = "gpio18";
				drive-strength = <16>;
				bias-disable;
			};
		};

		setb_7: setb_7 {
			mux {
				pins = "gpio19";
				function = "qdss_tracedata_b";
			};

			config {
				pins = "gpio19";
				drive-strength = <16>;
				bias-disable;
			};
		};

		setb_8: setb_8 {
			mux {
				pins = "gpio21";
				function = "qdss_tracedata_b";
			};

			config {
				pins = "gpio21";
				drive-strength = <16>;
				bias-disable;
			};
		};

		setb_9: setb_9 {
			mux {
				pins = "gpio22";
				function = "qdss_tracedata_b";
			};

			config {
				pins = "gpio22";
				drive-strength = <16>;
				bias-disable;
			};
		};

		setb_10: setb_10 {
			mux {
				pins = "gpio23";
				function = "qdss_tracedata_b";
			};

			config {
				pins = "gpio23";
				drive-strength = <16>;
				bias-disable;
			};
		};

		setb_11: setb_11 {
			mux {
				pins = "gpio26";
				function = "qdss_tracedata_b";
			};

			config {
				pins = "gpio26";
				drive-strength = <16>;
				bias-disable;
			};
		};

		setb_12: setb_12 {
			mux {
				pins = "gpio29";
				function = "qdss_tracedata_b";
			};

			config {
				pins = "gpio29";
				drive-strength = <16>;
				bias-disable;
			};
		};

		setb_13: setb_13 {
			mux {
				pins = "gpio57";
				function = "qdss_tracedata_b";
			};

			config {
				pins = "gpio57";
				drive-strength = <16>;
				bias-disable;
			};
		};

		setb_14: setb_14 {
			mux {
				pins = "gpio58";
				function = "qdss_tracedata_b";
			};

			config {
				pins = "gpio58";
				drive-strength = <16>;
				bias-disable;
			};
		};

		setb_15: setb_15 {
			mux {
				pins = "gpio91";
				function = "qdss_traceclk_b";
			};

			config {
				pins = "gpio91";
				drive-strength = <16>;
				bias-disable;
			};
		};

		setb_16: setb_16 {
			mux {
				pins = "gpio92";
				function = "qdss_tracedata_b";
			};

			config {
				pins = "gpio92";
				drive-strength = <16>;
				bias-disable;
			};
		};

		setb_17: setb_17 {
			mux {
				pins = "gpio93";
				function = "qdss_tracedata_b";
			};

			config {
				pins = "gpio93";
				drive-strength = <16>;
				bias-disable;
			};
		};

		setb_18: setb_18 {
			mux {
				pins = "gpio94";
				function = "qdss_tracectl_b";
			};

			config {
				pins = "gpio94";
				drive-strength = <16>;
				bias-disable;
			};
		};

		trigout_a: trigout_a {
			mux {
				pins = "gpio25";
				function = "qdss_cti_trig_out_a";
			};

			config {
				pins = "gpio25";
				drive-strength = <2>;
				bias-disable;
			};
		};

		tsif0_signals_active: tsif0_signals_active {
			tsif1_clk {
				pins = "gpio89"; /* TSIF0 CLK */
				function = "tsif1_clk";
			};
			tsif1_en {
				pins = "gpio90"; /* TSIF0 Enable */
				function = "tsif1_en";
			};
			tsif1_data {
				pins = "gpio91"; /* TSIF0 DATA */
				function = "tsif1_data";
			};
			signals_cfg {
				pins = "gpio89", "gpio90", "gpio91";
				drive_strength = <2>;	/* 2 mA */
				bias-pull-down;		/* pull down */
			};
		};

		/* sync signal is only used if configured to mode-2 */
		tsif0_sync_active: tsif0_sync_active {
			tsif1_sync {
				pins = "gpio39";	/* TSIF0 SYNC */
				function = "tsif1_sync";
				drive_strength = <2>;	/* 2 mA */
				bias-pull-down;		/* pull down */
			};
		};

		tsif1_signals_active: tsif1_signals_active {
			tsif2_clk {
				pins = "gpio93"; /* TSIF1 CLK */
				function = "tsif2_clk";
			};
			tsif2_en {
				pins = "gpio94"; /* TSIF1 Enable */
				function = "tsif2_en";
			};
			tsif2_data {
				pins = "gpio95"; /* TSIF1 DATA */
				function = "tsif2_data";
			};
			signals_cfg {
				pins = "gpio93", "gpio94", "gpio95";
				drive_strength = <2>;	/* 2 mA */
				bias-pull-down;		/* pull down */
			};
		};

		/* sync signal is only used if configured to mode-2 */
		tsif1_sync_active: tsif1_sync_active {
			tsif2_sync {
				pins = "gpio96";	/* TSIF1 SYNC */
				function = "tsif2_sync";
				drive_strength = <2>;	/* 2 mA */
				bias-pull-down;		/* pull down */
			};
		};

		ap2mdm {
			ap2mdm_active: ap2mdm_active {
				mux {
					/* ap2mdm-status
					 * ap2mdm-errfatal
					 * ap2mdm-vddmin
					 */
					pins = "gpio107", "gpio109", "gpio111";
					function = "gpio";
				};

				config {
					pins = "gpio107", "gpio109", "gpio111";
					drive-strength = <16>;
					bias-disable;
				};
			};
			ap2mdm_sleep: ap2mdm_sleep {
				mux {
					/* ap2mdm-status
					 * ap2mdm-errfatal
					 * ap2mdm-vddmin
					 */
					pins = "gpio107", "gpio109", "gpio111";
					function = "gpio";
				};

				config {
					pins = "gpio107", "gpio109", "gpio111";
					drive-strength = <8>;
					bias-disable;
				};

			};
		};

		mdm2ap {
			mdm2ap_active: mdm2ap_active {
				mux {
				/* mdm2ap-status
				 * mdm2ap-errfatal
				 * mdm2ap-vddmin
				 */
					pins = "gpio106", "gpio108", "gpio112";
					function = "gpio";
				};

				config {
					pins = "gpio106", "gpio108", "gpio112";
					drive-strength = <8>;
					bias-disable;
				};
			};
			mdm2ap_sleep: mdm2ap_sleep {
				mux {
					/* mdm2ap-status
					 * mdm2ap-errfatal
					 * mdm2ap-vddmin
					 */
					pins = "gpio106", "gpio108", "gpio112";
					function = "gpio";
				};

				config {
					pins = "gpio106", "gpio108", "gpio112";
					drive-strength = <8>;
					bias-disable;
				};
			};
		};
	};
};
